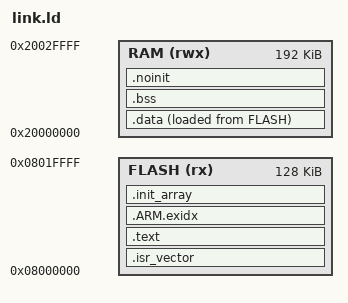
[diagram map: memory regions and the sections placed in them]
/* coact Renode harness linker script: STM32F407 Discovery memory map. */
ENTRY(Reset_Handler)

MEMORY
{
    FLASH (rx)  : ORIGIN = 0x08000000, LENGTH = 128K
    RAM   (rwx) : ORIGIN = 0x20000000, LENGTH = 192K
}

_estack = ORIGIN(RAM) + LENGTH(RAM);

SECTIONS
{
    .isr_vector :
    {
        KEEP(*(.isr_vector))
    } > FLASH

    .text :
    {
        *(.text*)
        *(.rodata*)
        . = ALIGN(4);
    } > FLASH

    .ARM.exidx :
    {
        *(.ARM.exidx*)
    } > FLASH

    /* C++ static constructors (FreeRTOS fixture needs FreeRtosResources /
       FreeRtos to be constructed; the other fixtures have none). */
    .init_array :
    {
        __init_array_start = .;
        KEEP(*(SORT(.init_array.*)))
        KEEP(*(.init_array))
        __init_array_end = .;
    } > FLASH

    _sidata = LOADADDR(.data);

    .data :
    {
        _sdata = .;
        *(.data*)
        . = ALIGN(4);
        _edata = .;
    } > RAM AT > FLASH

    .bss :
    {
        _sbss = .;
        *(.bss*)
        *(COMMON)
        . = ALIGN(4);
        _ebss = .;
    } > RAM

    /* Survives a machine reset: start.c zeroes only _sbss.._ebss and LoadELF
       has no file contents for a NOLOAD section, so the watchdog fixture can
       keep a boot counter and a pre-reset timestamp across an IWDG reset. */
    .noinit (NOLOAD) :
    {
        . = ALIGN(4);
        _snoinit = .;
        *(.noinit*)
        . = ALIGN(4);
        _enoinit = .;
    } > RAM
}
